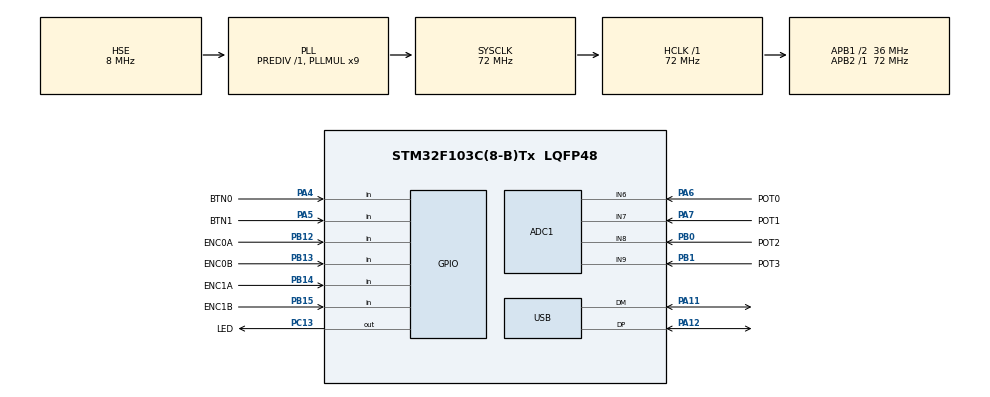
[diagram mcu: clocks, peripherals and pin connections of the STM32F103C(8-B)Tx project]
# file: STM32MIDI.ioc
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ADC1.Channel-0\#ChannelRegularConversion=ADC_CHANNEL_9
ADC1.ContinuousConvMode=ENABLE
ADC1.NbrOfConversionFlag=1
ADC1.Rank-0\#ChannelRegularConversion=1
ADC1.SamplingTime-0\#ChannelRegularConversion=ADC_SAMPLETIME_1CYCLE_5
ADC1.master=1
Mcu.Family=STM32F1
Mcu.Name=STM32F103C(8-B)Tx
Mcu.Package=LQFP48
NVIC.PriorityGroup=NVIC_PRIORITYGROUP_4
NVIC.USB_LP_CAN1_RX0_IRQn=true\:0\:0\:false\:false\:true\:false\:true
PA11.Mode=Device
PA11.Signal=USB_DM
PA12.Mode=Device
PA12.Signal=USB_DP
PA13.Mode=Serial_Wire
PA13.Signal=SYS_JTMS-SWDIO
PA14.Mode=Serial_Wire
PA14.Signal=SYS_JTCK-SWCLK
PA4.GPIO_Label=BTN0
PA4.GPIO_PuPd=GPIO_PULLUP
PA4.Signal=GPIO_Input
PA5.GPIO_Label=BTN1
PA5.GPIO_Mode=GPIO_MODE_INPUT
PA5.GPIO_PuPd=GPIO_PULLUP
PA5.Signal=GPIO_Input
PA6.GPIO_Label=POT0
PA6.Signal=ADCx_IN6
PA7.GPIO_Label=POT1
PA7.Signal=ADCx_IN7
PB0.GPIO_Label=POT2
PB0.Signal=ADCx_IN8
PB1.GPIO_Label=POT3
PB1.Signal=ADCx_IN9
PB12.GPIO_Label=ENC0A
PB12.GPIO_PuPd=GPIO_PULLUP
PB12.Signal=GPIO_Input
PB13.GPIO_Label=ENC0B
PB13.GPIO_PuPd=GPIO_PULLUP
PB13.Signal=GPIO_Input
PB14.GPIO_Label=ENC1A
PB14.GPIO_PuPd=GPIO_PULLUP
PB14.Signal=GPIO_Input
PB15.GPIO_Label=ENC1B
PB15.GPIO_PuPd=GPIO_PULLUP
PB15.Signal=GPIO_Input
PC13-TAMPER-RTC.GPIO_Label=LED
PC13-TAMPER-RTC.Signal=GPIO_Output
PC14-OSC32_IN.Mode=LSE-External-Oscillator
PC14-OSC32_IN.Signal=RCC_OSC32_IN
PC15-OSC32_OUT.Mode=LSE-External-Oscillator
PC15-OSC32_OUT.Signal=RCC_OSC32_OUT
PD0-OSC_IN.Mode=HSE-External-Oscillator
PD0-OSC_IN.Signal=RCC_OSC_IN
PD1-OSC_OUT.Mode=HSE-External-Oscillator
PD1-OSC_OUT.Signal=RCC_OSC_OUT
ProjectManager.HeapSize=0x200
ProjectManager.StackSize=0x400
ProjectManager.TargetToolchain=STM32CubeIDE
RCC.ADCPresc=RCC_ADCPCLK2_DIV6
RCC.AHBFreq_Value=72000000
RCC.APB1CLKDivider=RCC_HCLK_DIV2
RCC.APB1Freq_Value=36000000
RCC.APB1TimFreq_Value=72000000
RCC.APB2Freq_Value=72000000
RCC.APB2TimFreq_Value=72000000
RCC.HCLKFreq_Value=72000000
RCC.PLLMUL=RCC_PLL_MUL9
RCC.SYSCLKFreq_VALUE=72000000
RCC.SYSCLKSource=RCC_SYSCLKSOURCE_PLLCLK
RCC.USBFreq_Value=48000000
RCC.USBPrescaler=RCC_USBCLKSOURCE_PLL_DIV1_5
SH.ADCx_IN6.0=ADC1_IN6,IN6
SH.ADCx_IN7.0=ADC1_IN7,IN7
SH.ADCx_IN8.0=ADC1_IN8,IN8
SH.ADCx_IN9.0=ADC1_IN9,IN9
USB_DEVICE.APP_RX_DATA_SIZE=1000
USB_DEVICE.CLASS_NAME_FS=CDC
USB_DEVICE.MANUFACTURER_STRING=LuxARTS
USB_DEVICE.PRODUCT_STRING_CDC_FS=STM32MIDI
USB_DEVICE.VirtualMode=Cdc
USB_DEVICE.VirtualModeFS=Cdc_FS
VP_USB_DEVICE_VS_USB_DEVICE_CDC_FS.Mode=CDC_FS
board=custom

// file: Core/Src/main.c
/* USER CODE BEGIN Header */
/**
 ******************************************************************************
 * @file           : main.c
 * @brief          : Main program body
 ******************************************************************************
 * @attention
 *
 * <h2><center>&copy; Copyright (c) 2020 STMicroelectronics.
 * All rights reserved.</center></h2>
 *
 * This software component is licensed by ST under BSD 3-Clause license,
 * the "License"; You may not use this file except in compliance with the
 * License. You may obtain a copy of the License at:
 *                        opensource.org/licenses/BSD-3-Clause
 *
 ******************************************************************************
 */
/* USER CODE END Header */

#include "main.h"
#include "adc.h"
#include "usb_device.h"
#include "gpio.h"

/* USER CODE BEGIN Includes */
#include "midi.h"
#include "utils.h"
#include "pot.h"
/* USER CODE END Includes */

void SystemClock_Config(void);

int main(void) {

	/* MCU Configuration--------------------------------------------------------*/

	/* Reset of all peripherals, Initializes the Flash interface and the Systick. */
	HAL_Init();

	/* Configure the system clock */
	SystemClock_Config();

	/* Initialize all configured peripherals */
	MX_GPIO_Init();
	MX_ADC1_Init();
	MX_USB_DEVICE_Init();
	/* USER CODE BEGIN 2 */
	HAL_ADCEx_Calibration_Start(&hadc1);
	/* USER CODE END 2 */

	/* Infinite loop */
	while (1) {
		/* USER CODE BEGIN 3 */
		if(Pot_checkChanged(0)){
			MIDI_control(0, 10, Pot_getValue(0));
			HAL_Delay(20);
			HAL_GPIO_TogglePin(LED_GPIO_Port, LED_Pin);
		}
	}
	/* USER CODE END 3 */
}

void SystemClock_Config(void) {
	RCC_OscInitTypeDef RCC_OscInitStruct = { 0 };
	RCC_ClkInitTypeDef RCC_ClkInitStruct = { 0 };
	RCC_PeriphCLKInitTypeDef PeriphClkInit = { 0 };

	/** Initializes the CPU, AHB and APB busses clocks
	 */
	RCC_OscInitStruct.OscillatorType = RCC_OSCILLATORTYPE_HSE;
	RCC_OscInitStruct.HSEState = RCC_HSE_ON;
	RCC_OscInitStruct.HSEPredivValue = RCC_HSE_PREDIV_DIV1;
	RCC_OscInitStruct.HSIState = RCC_HSI_ON;
	RCC_OscInitStruct.PLL.PLLState = RCC_PLL_ON;
	RCC_OscInitStruct.PLL.PLLSource = RCC_PLLSOURCE_HSE;
	RCC_OscInitStruct.PLL.PLLMUL = RCC_PLL_MUL9;
	if (HAL_RCC_OscConfig(&RCC_OscInitStruct) != HAL_OK) {
		Error_Handler();
	}
	/** Initializes the CPU, AHB and APB busses clocks
	 */
	RCC_ClkInitStruct.ClockType = RCC_CLOCKTYPE_HCLK | RCC_CLOCKTYPE_SYSCLK
			| RCC_CLOCKTYPE_PCLK1 | RCC_CLOCKTYPE_PCLK2;
	RCC_ClkInitStruct.SYSCLKSource = RCC_SYSCLKSOURCE_PLLCLK;
	RCC_ClkInitStruct.AHBCLKDivider = RCC_SYSCLK_DIV1;
	RCC_ClkInitStruct.APB1CLKDivider = RCC_HCLK_DIV2;
	RCC_ClkInitStruct.APB2CLKDivider = RCC_HCLK_DIV1;

	if (HAL_RCC_ClockConfig(&RCC_ClkInitStruct, FLASH_LATENCY_2) != HAL_OK) {
		Error_Handler();
	}
	PeriphClkInit.PeriphClockSelection = RCC_PERIPHCLK_ADC | RCC_PERIPHCLK_USB;
	PeriphClkInit.AdcClockSelection = RCC_ADCPCLK2_DIV6;
	PeriphClkInit.UsbClockSelection = RCC_USBCLKSOURCE_PLL_DIV1_5;
	if (HAL_RCCEx_PeriphCLKConfig(&PeriphClkInit) != HAL_OK) {
		Error_Handler();
	}
}

void Error_Handler(void) {
}

/************************ (C) COPYRIGHT STMicroelectronics *****END OF FILE****/
